# PIC32CX0525SG12144 register map
Vendor: Microchip Technology; Series: 0525SG12; File version: 0
CPU: CM4 r1p0, little endian, no MPU, no FPU, 3 interrupt priority bits, 172 interrupts
Registers are 32-bit, read-write, reset 0x0 unless marked. A register's access mark holds for its fields unless they carry their own. Offsets are from the block's base; [hi:lo] are bit positions; {n}, {i} and the like mark numbered series.

## PCR — The Power, Clocks, and Resets (PCR) Section identifies clock sources, and reset inputs to the chip
Base 0x40080100
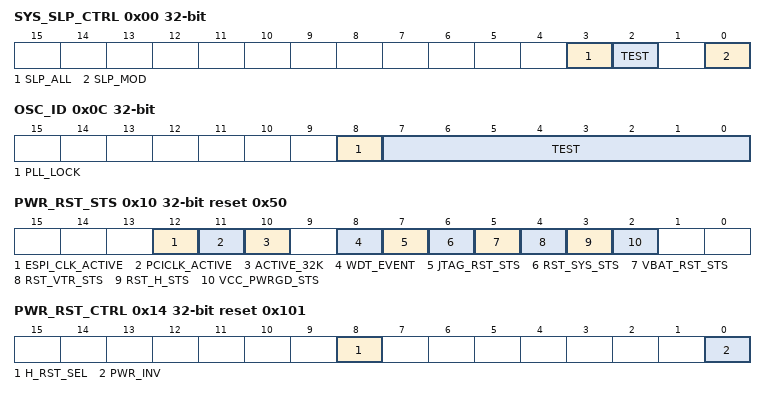
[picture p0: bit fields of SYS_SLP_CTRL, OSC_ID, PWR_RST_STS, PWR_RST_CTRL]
0x00 SYS_SLP_CTRL — System Sleep Control
  [3] SLP_ALL — Initiates the System Sleep mode
  [2] TEST — Test bit
  [0] SLP_MOD — Selects the System Sleep mode
0x04 PROC_CLK_CTRL reset 0x4 — Processor Clock Control Register [7:0] Processor Clock Divide Value (PROC_DIV)
  [7:0] DIV — Selects the EC clock rate
    1=DIVIDE_BY_1 (1: divide 48 MHz Ring Oscillator by 1); 3=DIVIDE_BY_3 (3: divide 48 MHz Ring Oscillator by 3); 4=DIVIDE_BY_4 (4: divide 48 MHz Ring Oscillator by 4); 16=DIVIDE_BY_16 (16: divide 48 MHz Ring Oscillator by 16); 48=DIVIDE_BY_48 (48: divide 48 MHz Ring Oscillator by 48)
0x08 SLOW_CLK_CTRL reset 0x1E0 — Configures the EC_CLK clock domain
  [9:0] DIV — SLOW_CLOCK_DIVIDE. n=Divide by n; 0=Clock off
0x0C OSC_ID — Oscillator ID Register
  [8] PLL_LOCK — PLL Lock Status
  [7:0] TEST — Test bits
0x10 PWR_RST_STS reset 0x50 — PCR Power Reset Status Register
  [12] ESPI_CLK_ACTIVE
  [11] PCICLK_ACTIVE — PCICLK_ACTIVE (PCICLK_ACTIVE)
  [10] ACTIVE_32K — ACTIVE_32K (32K_ACTIVE)
  [8] WDT_EVENT — Indicates that a WDT_EVENT happened. (R/W1C). 0 = Not active. 1 = A WDT_EVENT occured.
  [7] JTAG_RST_STS — Indicates status of JTAG_TRST# pin. 0 = No JTAG reset occurred since the last time this bit was cleared. 1 = A reset occurred because of a JTAG command.
  [6] RST_SYS_STS — Indicates the status of RESET_SYS.(R/W1C). 0 = No reset occurred since the last time this bit was cleared. 1 = A reset occurred.
  [5] VBAT_RST_STS — VBAT reset status 0 = No reset occurred while VTR was off or since the last time this bit was cleared. 1 = A reset occurred.(R/WC)
  [4] RST_VTR_STS — Indicates the status of RESET_VTR. 0 = reset active. 1 = reset not active.(R/W1C)
  [3] RST_H_STS — Indicates the status of RESET_VCC. 0 = reset active. 1 = reset not active.
  [2] VCC_PWRGD_STS — Indicates the status of VCC_PWRGD. 0 = PWRGD not asserted. 1 = PWRGD asserte.
0x14 PWR_RST_CTRL reset 0x101 — Power Reset Control Register
  [8] H_RST_SEL — Determines what generates the internal platform reset signal. 1=LRESET# pin; 0=eSPI PLTRST# VWire
  [0] PWR_INV — Used by FW to control internal RESET_VCC signal function and external PWROK pin. This bit is read-only when VCC_PWRGD is de-asserted low.
0x18 SYS_RST — System Reset Register
  [8] SOFT_SYS_RST — A write of a 1 forces an assertion of the RESET_SYS reset signal, resetting the device. A write of 0 has no effect.
0x30 SLP_EN_0 — Sleep Enable 0 Register
  [1] OTP_SLP_EN — OTP Enable
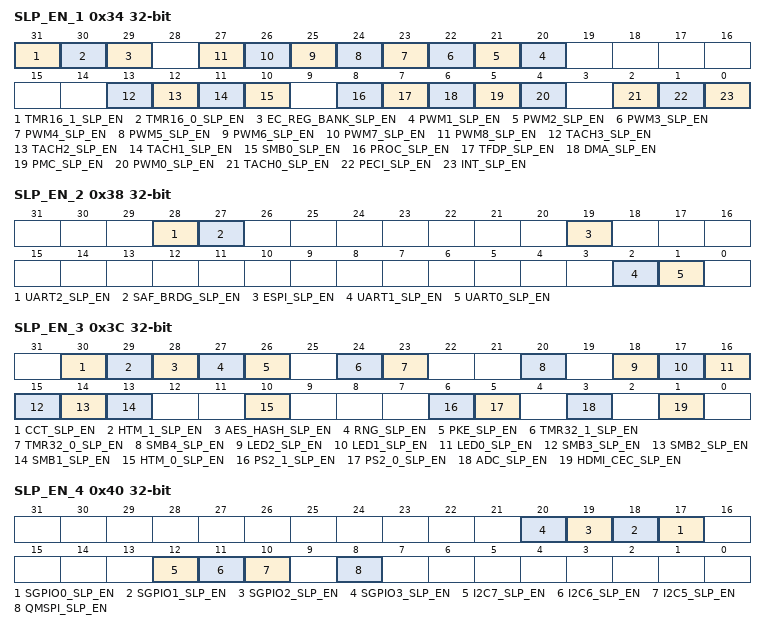
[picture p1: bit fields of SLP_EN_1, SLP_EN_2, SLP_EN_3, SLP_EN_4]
0x34 SLP_EN_1 — Sleep Enable 1 Register
  [31] TMR16_1_SLP_EN — TIMER16_1 Sleep Enable (TIMER16_1_SLP_EN)
  [30] TMR16_0_SLP_EN — TIMER16_0 Sleep Enable (TIMER16_0_SLP_EN)
  [29] EC_REG_BANK_SLP_EN — EC_REG_BANK Sleep Enable (EC_REG_BANK_SLP_EN)
  [n+19] PWM{n}_SLP_EN (n=1..8) — PWM{n} Sleep Enable (PWM{n}_SLP_EN)
  [13] TACH3_SLP_EN — TACH3 Sleep Enable (TACH3_SLP_EN)
  [12] TACH2_SLP_EN — TACH2 Sleep Enable (TACH2_SLP_EN)
  [11] TACH1_SLP_EN — TACH1 Sleep Enable (TACH1_SLP_EN)
  [10] SMB0_SLP_EN — SMB0 Sleep Enable (SMB0_SLP_EN)
  [8] PROC_SLP_EN — PROCESSOR Sleep Enable (PROCESSOR_SLP_EN)
  [7] TFDP_SLP_EN — TFDP Sleep Enable (TFDP_SLP_EN)
  [6] DMA_SLP_EN — DMA Sleep Enable (DMA_SLP_EN)
  [5] PMC_SLP_EN — PMC Sleep Enable (PMC_SLP_EN)
  [4] PWM0_SLP_EN — PWM0 Sleep Enable (PWM0_SLP_EN)
  [2] TACH0_SLP_EN — TACH0 Sleep Enable (TACH0_SLP_EN)
  [1] PECI_SLP_EN — PECI Sleep Enable
  [0] INT_SLP_EN — Interrupt Sleep Enable
0x38 SLP_EN_2 — Sleep Enable 2 Register
  [28] UART2_SLP_EN — UART 2 Sleep Enable
  [27] SAF_BRDG_SLP_EN — SAF BRIDGE Sleep Enable
  [19] ESPI_SLP_EN — eSPI Sleep Enable
  [2] UART1_SLP_EN — UART 1 Sleep Enable
  [1] UART0_SLP_EN — UART 0 Sleep Enable
0x3C SLP_EN_3 — Sleep Enable 3 Register
  [30] CCT_SLP_EN — Capture Compare Timer Sleep Enable (CCTIMER_SLP_EN)
  [29] HTM_1_SLP_EN — Hibernation TIMER 1 Sleep Enable (HTM_1_SLP_EN)
  [28] AES_HASH_SLP_EN — AES_HASH Sleep Enable
  [27] RNG_SLP_EN — RNG Sleep Enable
  [26] PKE_SLP_EN — PKE Sleep Enable
  [24] TMR32_1_SLP_EN — TIMER32_1 Sleep Enable (TIMER32_1_SLP_EN)
  [23] TMR32_0_SLP_EN — TIMER32_0 Sleep Enable (TIMER32_0_SLP_EN)
  [20] SMB4_SLP_EN — SMB4 Sleep Enable (SMB4_SLP_EN)
  [18] LED2_SLP_EN — LED2 Sleep Enable (LED2_SLP_EN)
  [17] LED1_SLP_EN — LED1 Sleep Enable (LED1_SLP_EN)
  [16] LED0_SLP_EN — LED0 Sleep Enable (LED0_SLP_EN)
  [15] SMB3_SLP_EN — SMB3 Sleep Enable (SMB3_SLP_EN)
  [14] SMB2_SLP_EN — SMB2 Sleep Enable (SMB2_SLP_EN)
  [13] SMB1_SLP_EN — SMB1 Sleep Enable (SMB1_SLP_EN)
  [10] HTM_0_SLP_EN — Hibernation Timer 0 Sleep Enable (HTM_0_SLP_EN)
  [6] PS2_1_SLP_EN — PS2_1 Sleep Enable (PS2_1_SLP_EN)
  [5] PS2_0_SLP_EN — PS2_0 Sleep Enable (PS2_0_SLP_EN)
  [3] ADC_SLP_EN — ADC Sleep Enable (ADC_SLP_EN)
  [1] HDMI_CEC_SLP_EN — HDMI_CEC Sleep Enable (ADC_SLP_EN)
0x40 SLP_EN_4 — Sleep Enable 4 Register
  [n+17] SGPIO{n}_SLP_EN (n=0..3) — SGPIO{n} Sleep Enable (SGPIO{n}_SLP_EN)
  [12] I2C7_SLP_EN — I2C7 Sleep Enable (I2C7_SLP_EN)
  [11] I2C6_SLP_EN — I2C6 Sleep Enable (I2C6_SLP_EN)
  [10] I2C5_SLP_EN — I2C5 Sleep Enable (I2C5_SLP_EN)
  [8] QMSPI_SLP_EN — Quad Master SPI Sleep Enable
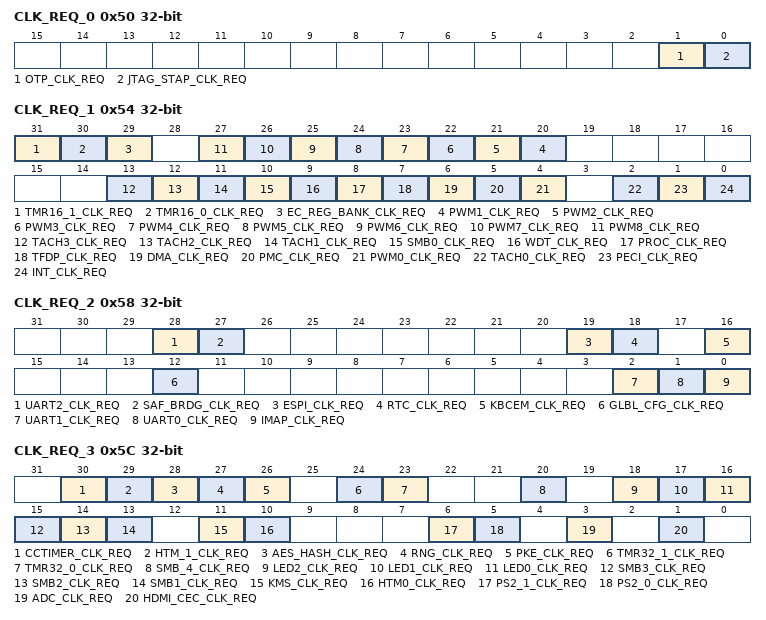
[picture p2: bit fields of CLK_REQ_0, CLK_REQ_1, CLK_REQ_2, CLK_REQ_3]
0x50 CLK_REQ_0 — Clock Required 0 Register
  [1] OTP_CLK_REQ — OTP Enable
  [0] JTAG_STAP_CLK_REQ — JTAG STAP Enable
0x54 CLK_REQ_1 — Clock Required 1 Register
  [31] TMR16_1_CLK_REQ — TIMER16_1 Clock Required (TIMER16_1_CLK_REQ)
  [30] TMR16_0_CLK_REQ — TIMER16_0 Clock Required (TIMER16_0_CLK_REQ)
  [29] EC_REG_BANK_CLK_REQ — EC_REG_BANK Clock Required (EC_REG_BANK_CLK_REQ)
  [n+19] PWM{n}_CLK_REQ (n=1..8) — PWM{n} Clock Required (PWM{n}_CLK_REQ)
  [13] TACH3_CLK_REQ — TACH3 Clock Required (TACH3_CLK_REQ)
  [12] TACH2_CLK_REQ — TACH2 Clock Required (TACH2_CLK_REQ)
  [11] TACH1_CLK_REQ — TACH1 Clock Required (TACH1_CLK_REQ)
  [10] SMB0_CLK_REQ — SMB0 Clock Required (SMB0_CLK_REQ)
  [9] WDT_CLK_REQ — WDT Clock Required (WDT_CLK_REQ)
  [8] PROC_CLK_REQ — PROCESSOR Clock Required (PROCESSOR_CLK_REQ)
  [7] TFDP_CLK_REQ — TFDP Clock Required (TFDP_CLK_REQ)
  [6] DMA_CLK_REQ — DMA Clock Required (DMA_CLK_REQ)
  [5] PMC_CLK_REQ — PMC Clock Required (PMC_CLK_REQ)
  [4] PWM0_CLK_REQ — PWM0 Clock Required (PWM0_CLK_REQ)
  [2] TACH0_CLK_REQ — TACH0 Clock Required (TACH0_CLK_REQ)
  [1] PECI_CLK_REQ — PECI Clock Required
  [0] INT_CLK_REQ — Interrupt Clock Required
0x58 CLK_REQ_2 — Clock Required 2 Register
  [28] UART2_CLK_REQ — UART 2 Clock Required
  [27] SAF_BRDG_CLK_REQ — SAF BRIDGE Clock Required
  [19] ESPI_CLK_REQ — eSPI Clock Required
  [18] RTC_CLK_REQ — RTC Clock Required (RTC_CLK_REQ)
  [16] KBCEM_CLK_REQ — 8042EM Clock Required (8042EM_CLK_REQ)
  [12] GLBL_CFG_CLK_REQ — GLBL_CFG (GLBL_CFG_CLK_REQ)
  [2] UART1_CLK_REQ — UART 1 Clock Required
  [1] UART0_CLK_REQ — UART 0 Clock Required
  [0] IMAP_CLK_REQ — IMAP Clock Required (IMAP_CLK_REQ)
0x5C CLK_REQ_3 — Clock Required 3 Register
  [30] CCTIMER_CLK_REQ — Capture Compare Timer Clock Required (CCTIMER_CLK_REQ)
  [29] HTM_1_CLK_REQ — Hibernation TIMER 1 Clock Required (HTM_1_CLK_REQ)
  [28] AES_HASH_CLK_REQ — AES_HASH Clock Required
  [27] RNG_CLK_REQ — RNG Clock Required
  [26] PKE_CLK_REQ — PKE Clock Required
  [24] TMR32_1_CLK_REQ — TIMER32_1 Clock Required (TIMER32_1_CLK_REQ)
  [23] TMR32_0_CLK_REQ — TIMER32_0 Clock Required (TIMER32_0_CLK_REQ)
  [20] SMB_4_CLK_REQ — SMB 4 Clock Required (SMB_4_CLK_REQ)
  [18] LED2_CLK_REQ — LED2 Clock Required (LED2_CLK_REQ)
  [17] LED1_CLK_REQ — LED1 Clock Required (LED1_CLK_REQ)
  [16] LED0_CLK_REQ — LED0 Clock Required (LED0_CLK_REQ)
  [15] SMB3_CLK_REQ — SMB3 Clock Required (SMB3_CLK_REQ)
  [14] SMB2_CLK_REQ — SMB2 Clock Required (SMB2_CLK_REQ)
  [13] SMB1_CLK_REQ — SMB1 Clock Required (SMB1_CLK_REQ)
  [11] KMS_CLK_REQ — KEYSCAN Clock Required (KMS_CLK_REQ)
  [10] HTM0_CLK_REQ — Hibernation TIMER 0 Clock Required (HTM_0_CLK_REQ)
  [6] PS2_1_CLK_REQ — PS2_1 Clock Required (PS2_1_CLK_REQ)
  [5] PS2_0_CLK_REQ — PS2_0 Clock Required (PS2_0_CLK_REQ)
  [3] ADC_CLK_REQ — ADC Clock Required (ADC_CLK_REQ)
  [1] HDMI_CEC_CLK_REQ — HDMI_CEC Clock Required (ADC_CLK_REQ)
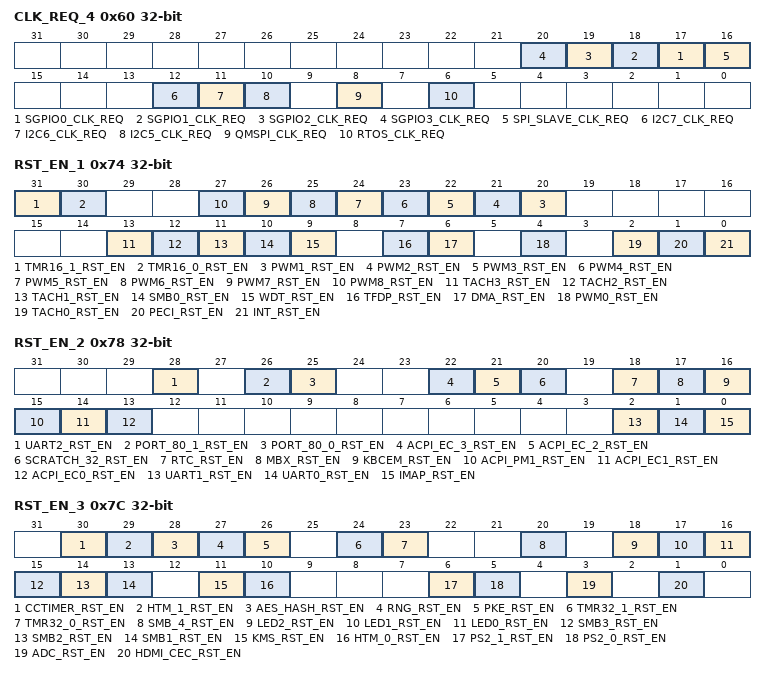
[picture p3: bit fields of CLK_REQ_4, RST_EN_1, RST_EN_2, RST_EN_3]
0x60 CLK_REQ_4 — Clock Required 4 Register
  [n+17] SGPIO{n}_CLK_REQ (n=0..3) — SGPIO{n} Clock Required (SGPIO{n}_CLK_REQ)
  [16] SPI_SLAVE_CLK_REQ — SPI SLAVE Clock Required (SPI_SLAVE_CLK_REQ)
  [12] I2C7_CLK_REQ — I2C7 Clock Required (I2C7_CLK_REQ)
  [11] I2C6_CLK_REQ — I2C6 Clock Required (I2C6_CLK_REQ)
  [10] I2C5_CLK_REQ — I2C5 Clock Required (I2C5_CLK_REQ)
  [8] QMSPI_CLK_REQ — Quad Master SPI Clock Required
  [6] RTOS_CLK_REQ — RTOS Clock Required (RTOS_CLK_REQ)
0x70 RST_EN_0 — Reset Enable 0 Register
  [1] OTP_RST_EN — OTP Reset Enable
0x74 RST_EN_1 — Reset Enable 1 Register
  [31] TMR16_1_RST_EN — TIMER16_1 Reset Enable (TIMER16_1_RST_EN)
  [30] TMR16_0_RST_EN — TIMER16_0 Reset Enable (TIMER16_0_RST_EN)
  [n+19] PWM{n}_RST_EN (n=1..8) — PWM{n} Reset Enable (PWM{n}_RST_EN)
  [13] TACH3_RST_EN — TACH3 Reset Enable (TACH3_RST_EN)
  [12] TACH2_RST_EN — TACH2 Reset Enable (TACH2_RST_EN)
  [11] TACH1_RST_EN — TACH1 Reset Enable (TACH1_RST_EN)
  [10] SMB0_RST_EN — SMB0 Reset Enable (SMB0_RST_EN)
  [9] WDT_RST_EN — WDT Reset Enable (WDT_RST_EN)
  [7] TFDP_RST_EN — TFDP Reset Enable (TFDP_RST_EN)
  [6] DMA_RST_EN — DMA Reset Enable (DMA_RST_EN)
  [4] PWM0_RST_EN — PWM0 Reset Enable (PWM0_RST_EN)
  [2] TACH0_RST_EN — TACH0 Reset Enable (TACH0_RST_EN)
  [1] PECI_RST_EN — PECI Reset Enable
  [0] INT_RST_EN — Interrupt Reset Enable
0x78 RST_EN_2 — Reset Enable 2 Register
  [28] UART2_RST_EN — UART 2 Reset Enable
  [26] PORT_80_1_RST_EN — Port 80 1 Reset Enable
  [25] PORT_80_0_RST_EN — Port 80 0 Reset Enable
  [22] ACPI_EC_3_RST_EN — ACPI EC 3 Reset Enable (ACPI_EC_3_RST_EN)
  [21] ACPI_EC_2_RST_EN — ACPI EC 2 Reset Enable (ACPI_EC_2_RST_EN)
  [20] SCRATCH_32_RST_EN — SCRATCH 32 Reset Enable
  [18] RTC_RST_EN — RTC Reset Enable (RTC_RST_EN)
  [17] MBX_RST_EN — Mailbox Reset Enable (MBX_RST_EN)
  [16] KBCEM_RST_EN — 8042EM Reset Enable (8042EM_RST_EN)
  [15] ACPI_PM1_RST_EN — ACPI PM1 Reset Enable (ACPI_PM1_RST_EN)
  [14] ACPI_EC1_RST_EN — ACPI EC 1 Reset Enable (ACPI_EC_1_RST_EN)
  [13] ACPI_EC0_RST_EN — ACPI EC 0 Reset Enable (ACPI_EC_0_RST_EN)
  [2] UART1_RST_EN — UART 1 Reset Enable
  [1] UART0_RST_EN — UART 0 Reset Enable
  [0] IMAP_RST_EN — IMAP Reset Enable (IMAP_RST_EN)
0x7C RST_EN_3 — Reset Enable 3 Register
  [30] CCTIMER_RST_EN — Capture Compare Timer Reset Enable (CCTIMER_RST_EN)
  [29] HTM_1_RST_EN — Hibernation TIMER 1 Reset Enable (HTM_1_RST_EN)
  [28] AES_HASH_RST_EN — AES_HASH Reset Enable
  [27] RNG_RST_EN — RNG Reset Enable
  [26] PKE_RST_EN — PKE Reset Enable
  [24] TMR32_1_RST_EN — TIMER32_1 Reset Enable (TIMER32_1_RST_EN)
  [23] TMR32_0_RST_EN — TIMER32_0 Reset Enable (TIMER32_0_RST_EN)
  [20] SMB_4_RST_EN — SMB 4 Reset Enable (SMB_4_RST_EN)
  [18] LED2_RST_EN — LED2 Reset Enable (LED2_RST_EN)
  [17] LED1_RST_EN — LED1 Reset Enable (LED1_RST_EN)
  [16] LED0_RST_EN — LED0 Reset Enable (LED0_RST_EN)
  [15] SMB3_RST_EN — SMB3 Reset Enable (SMB3_RST_EN)
  [14] SMB2_RST_EN — SMB2 Reset Enable (SMB2_RST_EN)
  [13] SMB1_RST_EN — SMB1 Reset Enable (SMB1_RST_EN)
  [11] KMS_RST_EN — KEYSCAN Reset Enable (KMS_RST_EN)
  [10] HTM_0_RST_EN — Hibernation TIMER 0 Reset Enable (HTM_0_RST_EN)
  [6] PS2_1_RST_EN — PS2_1 Reset Enable (PS2_1_RST_EN)
  [5] PS2_0_RST_EN — PS2_0 Reset Enable (PS2_0_RST_EN)
  [3] ADC_RST_EN — ADC Reset Enable (ADC_RST_EN)
  [1] HDMI_CEC_RST_EN — HDMI_CEC Reset Enable (HDMI_CEC_RST_EN)
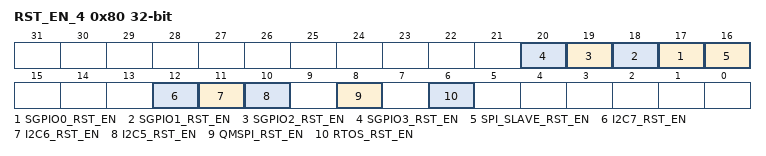
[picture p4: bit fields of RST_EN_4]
0x80 RST_EN_4 — Reset Enable 4 Register
  [n+17] SGPIO{n}_RST_EN (n=0..3) — SGPIO{n} Reset Enable (SGPIO{n}_RST_EN)
  [16] SPI_SLAVE_RST_EN — SPI SLAVE Reset Enable (SPI_SLAVE_RST_EN)
  [12] I2C7_RST_EN — I2C7 Reset Enable (I2C7_RST_EN)
  [11] I2C6_RST_EN — I2C6 Reset Enable (I2C6_RST_EN)
  [10] I2C5_RST_EN — I2C5 Reset Enable (I2C5_RST_EN)
  [8] QMSPI_RST_EN — Quad Master SPI Reset Enable
  [6] RTOS_RST_EN — RTOS Reset Enable (RTOS_RST_EN)
0x84 LOCK_REG reset 0xA6382D4D — LOCK Register
  [31:0] PCR_RST_EN_LOCK — PCR Reset Enable Lock Register.
